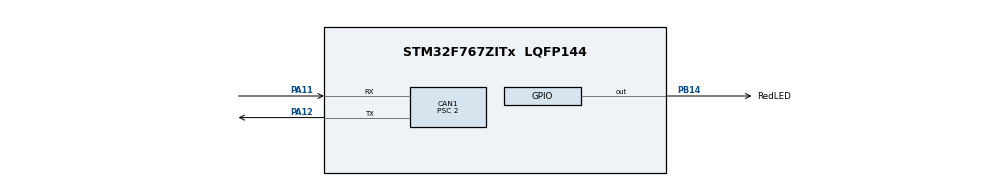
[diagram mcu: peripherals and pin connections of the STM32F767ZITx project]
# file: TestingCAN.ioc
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CAN1.BS1=CAN_BS1_13TQ
CAN1.BS2=CAN_BS2_2TQ
CAN1.CalculateBaudRate=500000
CAN1.CalculateTimeBit=2000
CAN1.CalculateTimeQuantum=125.0
CAN1.Mode=CAN_MODE_SILENT
CAN1.Prescaler=2
CAN1.SJW=CAN_SJW_1TQ
Mcu.Family=STM32F7
Mcu.Name=STM32F767ZITx
Mcu.Package=LQFP144
NVIC.PriorityGroup=NVIC_PRIORITYGROUP_4
PA11.Mode=CAN_Activate
PA11.Signal=CAN1_RX
PA12.Mode=CAN_Activate
PA12.Signal=CAN1_TX
PB14.GPIO_Label=RedLED
PB14.Signal=GPIO_Output
ProjectManager.HeapSize=0x200
ProjectManager.StackSize=0x400
ProjectManager.TargetToolchain=STM32CubeIDE
RCC.HSE_VALUE=25000000
RCC.HSI_VALUE=16000000
RCC.LSE_VALUE=32768
RCC.USBFreq_Value=96000000
RCC.VCOOutputFreq_Value=192000000
board=custom

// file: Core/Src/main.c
/* USER CODE BEGIN Header */
/**
  ******************************************************************************
  * @file           : main.c
  * @brief          : Main program body
  ******************************************************************************
  * @attention
  *
  * Copyright (c) 2023 STMicroelectronics.
  * All rights reserved.
  *
  * This software is licensed under terms that can be found in the LICENSE file
  * in the root directory of this software component.
  * If no LICENSE file comes with this software, it is provided AS-IS.
  *
  ******************************************************************************
  */
/* USER CODE END Header */
#include "main.h"

CAN_HandleTypeDef hcan1;

void SystemClock_Config(void);
static void MX_GPIO_Init(void);
static void MX_CAN1_Init(void);
/* USER CODE BEGIN PFP */
void CAN_Filter_Config(void);
void CAN_Rx();
/* USER CODE END PFP */

int main(void)
{

  /* MCU Configuration--------------------------------------------------------*/

  /* Reset of all peripherals, Initializes the Flash interface and the Systick. */
  HAL_Init();

  /* Configure the system clock */
  SystemClock_Config();

  /* Initialize all configured peripherals */
  MX_GPIO_Init();
  CAN_Filter_Config();
  MX_CAN1_Init();
  /* USER CODE BEGIN 2 */
//  CAN_Filter_Config();
  HAL_CAN_Start(&hcan1);
  /* USER CODE END 2 */

  /* Infinite loop */
  /* USER CODE BEGIN WHILE */
  int received = 0;
  while (1)
  {
    /* USER CODE END WHILE */

    /* USER CODE BEGIN 3 */
	  CAN_Rx();
	  if(++received > 10) {
		  HAL_GPIO_TogglePin(RedLED_GPIO_Port, RedLED_Pin);
		  received = 0;
	  }
  }
  /* USER CODE END 3 */
}

void SystemClock_Config(void)
{
  RCC_OscInitTypeDef RCC_OscInitStruct = {0};
  RCC_ClkInitTypeDef RCC_ClkInitStruct = {0};

  /** Configure the main internal regulator output voltage
  */
  __HAL_RCC_PWR_CLK_ENABLE();
  __HAL_PWR_VOLTAGESCALING_CONFIG(PWR_REGULATOR_VOLTAGE_SCALE3);

  /** Initializes the RCC Oscillators according to the specified parameters
  * in the RCC_OscInitTypeDef structure.
  */
  RCC_OscInitStruct.OscillatorType = RCC_OSCILLATORTYPE_HSI;
  RCC_OscInitStruct.HSIState = RCC_HSI_ON;
  RCC_OscInitStruct.HSICalibrationValue = RCC_HSICALIBRATION_DEFAULT;
  RCC_OscInitStruct.PLL.PLLState = RCC_PLL_NONE;
  if (HAL_RCC_OscConfig(&RCC_OscInitStruct) != HAL_OK)
  {
    Error_Handler();
  }

  /** Initializes the CPU, AHB and APB buses clocks
  */
  RCC_ClkInitStruct.ClockType = RCC_CLOCKTYPE_HCLK|RCC_CLOCKTYPE_SYSCLK
                              |RCC_CLOCKTYPE_PCLK1|RCC_CLOCKTYPE_PCLK2;
  RCC_ClkInitStruct.SYSCLKSource = RCC_SYSCLKSOURCE_HSI;
  RCC_ClkInitStruct.AHBCLKDivider = RCC_SYSCLK_DIV1;
  RCC_ClkInitStruct.APB1CLKDivider = RCC_HCLK_DIV1;
  RCC_ClkInitStruct.APB2CLKDivider = RCC_HCLK_DIV1;

  if (HAL_RCC_ClockConfig(&RCC_ClkInitStruct, FLASH_LATENCY_0) != HAL_OK)
  {
    Error_Handler();
  }
}

static void MX_CAN1_Init(void)
{

  hcan1.Instance = CAN1;
  hcan1.Init.Prescaler = 2;
  hcan1.Init.Mode = CAN_MODE_SILENT;
  hcan1.Init.SyncJumpWidth = CAN_SJW_1TQ;
  hcan1.Init.TimeSeg1 = CAN_BS1_13TQ;
  hcan1.Init.TimeSeg2 = CAN_BS2_2TQ;
  hcan1.Init.TimeTriggeredMode = DISABLE;
  hcan1.Init.AutoBusOff = DISABLE;
  hcan1.Init.AutoWakeUp = ENABLE;
  hcan1.Init.AutoRetransmission = ENABLE;
  hcan1.Init.ReceiveFifoLocked = DISABLE;
  hcan1.Init.TransmitFifoPriority = DISABLE;
  if (HAL_CAN_Init(&hcan1) != HAL_OK)
  {
    Error_Handler();
  }

}

static void MX_GPIO_Init(void)
{
  GPIO_InitTypeDef GPIO_InitStruct = {0};

  /* GPIO Ports Clock Enable */
  __HAL_RCC_GPIOB_CLK_ENABLE();
  __HAL_RCC_GPIOA_CLK_ENABLE();

  /*Configure GPIO pin Output Level */
  HAL_GPIO_WritePin(RedLED_GPIO_Port, RedLED_Pin, GPIO_PIN_RESET);

  /*Configure GPIO pin : RedLED_Pin */
  GPIO_InitStruct.Pin = RedLED_Pin;
  GPIO_InitStruct.Mode = GPIO_MODE_OUTPUT_PP;
  GPIO_InitStruct.Pull = GPIO_NOPULL;
  GPIO_InitStruct.Speed = GPIO_SPEED_FREQ_LOW;
  HAL_GPIO_Init(RedLED_GPIO_Port, &GPIO_InitStruct);

}

/* USER CODE BEGIN 4 */
void CAN_Filter_Config(void){
	CAN_FilterTypeDef can1_filter_init;

	can1_filter_init.FilterActivation = DISABLE;
	can1_filter_init.FilterFIFOAssignment = CAN_RX_FIFO0;

	if(HAL_CAN_ConfigFilter(&hcan1, &can1_filter_init) != HAL_OK){
		Error_Handler();
	}
}

void CAN_Rx(void) {
	CAN_RxHeaderTypeDef RxHeader;
	uint8_t rcvd_msg[5];
	while(! HAL_CAN_GetRxFifoFillLevel(&hcan1, CAN_RX_FIFO0));
	if(HAL_CAN_GetRxMessage(&hcan1, CAN_RX_FIFO0, &RxHeader, rcvd_msg) != HAL_OK) {
		Error_Handler();
	}
}
/* USER CODE END 4 */

void Error_Handler(void)
{
  __disable_irq();
  while (1)
  {
  }
}
